# MCU_NAVSS0_SEC_PROXY0_CFG register map
Vendor: Texas Instruments
Peripheral module from a debugger description file (folder J7ES).
Registers are 32-bit, read-only, reset 0x66363100 unless marked. A register's access mark holds for its fields unless they carry their own. Offsets are as the file gives them; lines under a group give offsets from that group; [hi:lo] are bit positions; {n}, {i} and the like mark numbered series; 'fields as' and 'values as' point back to an identical list; <NAME> marks a mode.

## MCU_NAVSS0_SEC_PROXY0_CFG
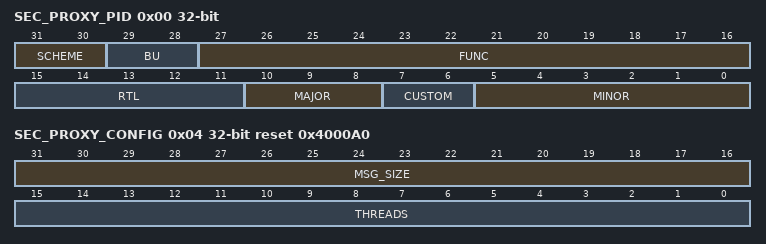
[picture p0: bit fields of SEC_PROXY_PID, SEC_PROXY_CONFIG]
0x00 SEC_PROXY_PID — The Revision Register contains the major and minor revisions for the module.
  [31:30] SCHEME
  [29:28] BU
  [27:16] FUNC — Module ID
  [15:11] RTL — RTL revision. Will vary depending on release.
  [10:8] MAJOR — Major revision
  [7:6] CUSTOM
  [5:0] MINOR — Minor revision
0x04 SEC_PROXY_CONFIG reset 0x4000A0 — The Config Register shows configured params.
  [31:16] MSG_SIZE — Supported message size in bytes.
  [15:0] THREADS — Number of proxy threads supported.
